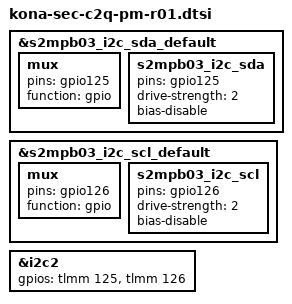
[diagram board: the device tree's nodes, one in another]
/* Copyright (c) 2014, The Linux Foundation. All rights reserved.
 *
 * This program is free software; you can redistribute it and/or modify
 * it under the terms of the GNU General Public License version 2 and
 * only version 2 as published by the Free Software Foundation.
 *
 * This program is distributed in the hope that it will be useful,
 * but WITHOUT ANY WARRANTY; without even the implied warranty of
 * MERCHANTABILITY or FITNESS FOR A PARTICULAR PURPOSE.  See the
 * GNU General Public License for more details.
 */

#include <dt-bindings/regulator/qcom,rpmh-regulator-levels.h>

&s2mpb03_i2c_sda_default {
	mux {
		pins = "gpio125";
		function = "gpio";
	};
	s2mpb03_i2c_sda {
		pins = "gpio125";
		drive-strength = <2>;
		bias-disable;
	};
};

&s2mpb03_i2c_scl_default {
	mux {
		pins = "gpio126";
		function = "gpio";
	};
	s2mpb03_i2c_scl {
		pins = "gpio126";
		drive-strength = <2>;
		bias-disable;
	};
};

/* S2MPB03 Camera PMIC */
&i2c2 {
	gpios = <&tlmm 125 0 /* sda */
		&tlmm 126 0 /* scl */
	>;
};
